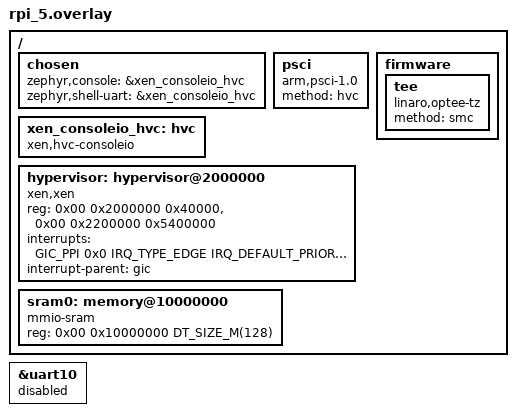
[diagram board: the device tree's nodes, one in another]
/*
 * Copyright (C) 2024 EPAM Systems.
 *
 * SPDX-License-Identifier: Apache-2.0
 */

 /delete-node/ &sram0;

#include <mem.h>

/ {
	#address-cells = <2>;
	#size-cells = <1>;

       chosen {
               zephyr,console = &xen_consoleio_hvc;
               zephyr,shell-uart = &xen_consoleio_hvc;
       };

       psci {
       compatible = "arm,psci-1.0", "arm,psci-0.2", "arm,psci";
               method = "hvc";
       };

       xen_consoleio_hvc: hvc {
               compatible = "xen,hvc-consoleio";
               status = "okay";
       };


	/*
	 * This node may differs on different setups, please check
	 * following line in Xen boot log to set it right:
	 * (XEN) Grant table range: 0x00000002800000-0x00000002840000
	 * Also, add extended region 1:
	 * (XEN) d0: extended region 1: 0x40000000->0x5fe00000
	 *
	 * Xen passes actual values for setup in domain device tree, but Zephyr
	 * is not capable to parse and handle it in runtime.
	 */
	hypervisor: hypervisor@2000000 {
		compatible = "xen,xen";
		reg = <0x00 0x2000000 0x40000>, <0x00 0x2200000 0x5400000>;
		interrupts = <GIC_PPI 0x0 IRQ_TYPE_EDGE IRQ_DEFAULT_PRIORITY>;
		interrupt-parent = <&gic>;
		status = "okay";
	};

	/*
	 * This node may differs on different setups, because Xen picks
	 * region for Domain-0 for every specific configuration. You can
	 * start Xen for your platform and check following log:
	 * (XEN) Allocating 1:1 mappings totalling 512MB for dom0:
	 * (XEN) BANK[0] 0x00000060000000-0x00000080000000 (512MB)
	 * (XEN) Loading zImage from 0000000000080000 to 0000000060000000-0000000060038004
	 *
	 * Xen passes actual values for setup in domain device tree, but Zephyr
	 * is not capable to parse and handle it in runtime.
	 */
	sram0: memory@10000000 {
		compatible = "mmio-sram";
		reg = <0x00 0x10000000 DT_SIZE_M(128)>;
	};

    firmware {
	tee {
	compatible = "linaro,optee-tz";
	method = "smc";
	status = "okay";
	};
    };

};

&uart10 {
	status = "disabled";
};
